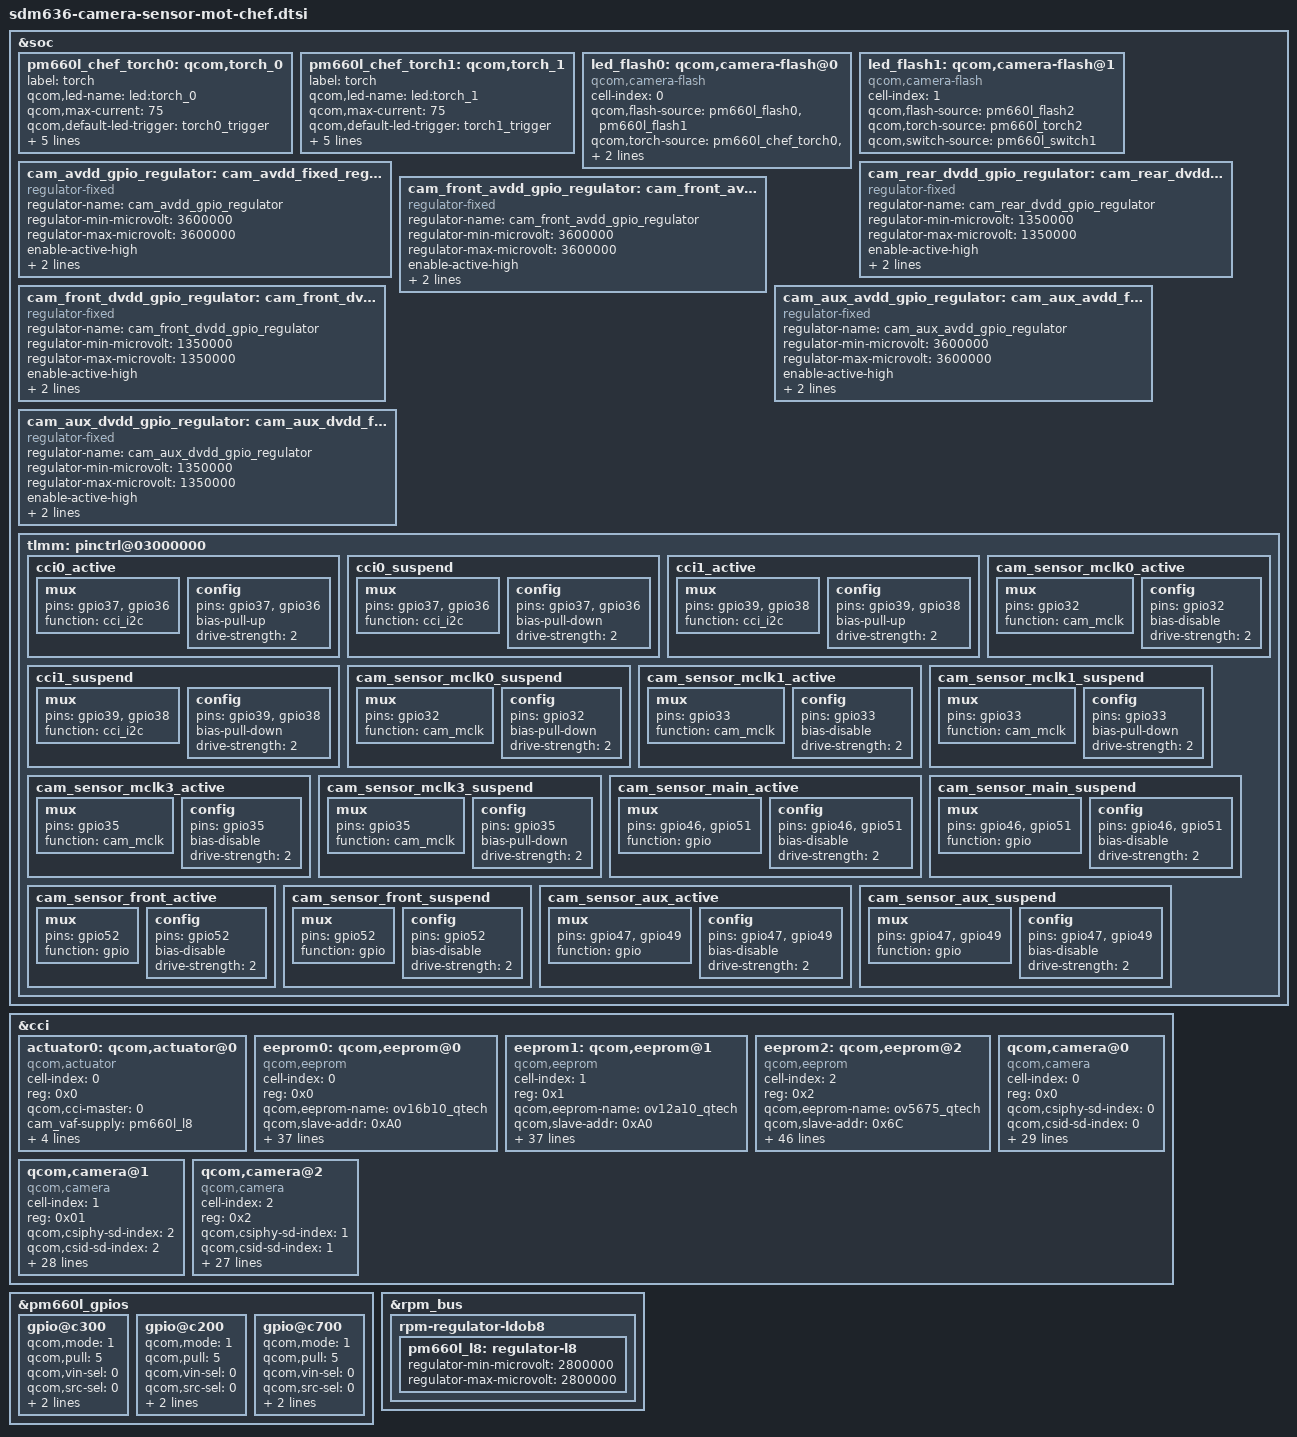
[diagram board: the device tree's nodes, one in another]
/*
 * Copyright (c) 2016-2017, The Linux Foundation. All rights reserved.
 *
 * This program is free software; you can redistribute it and/or modify
 * it under the terms of the GNU General Public License version 2 and
 * only version 2 as published by the Free Software Foundation.
 *
 * This program is distributed in the hope that it will be useful,
 * but WITHOUT ANY WARRANTY; without even the implied warranty of
 * MERCHANTABILITY or FITNESS FOR A PARTICULAR PURPOSE.  See the
 * GNU General Public License for more details.
 */

&soc {
	pm660l_chef_torch0: qcom,torch_0 {
				label = "torch";
				qcom,led-name = "led:torch_0";
				qcom,max-current = <75>;
				qcom,default-led-trigger = "torch0_trigger";
				qcom,id = <0>;
				qcom,current-ma = <75>;
				qcom,ires-ua = <12500>;
				qcom,hdrm-voltage-mv = <325>;
				qcom,hdrm-vol-hi-lo-win-mv = <100>;
			};

	pm660l_chef_torch1: qcom,torch_1 {
				label = "torch";
				qcom,led-name = "led:torch_1";
				qcom,max-current = <75>;
				qcom,default-led-trigger = "torch1_trigger";
				qcom,id = <1>;
				qcom,current-ma = <75>;
				qcom,ires-ua = <12500>;
				qcom,hdrm-voltage-mv = <325>;
				qcom,hdrm-vol-hi-lo-win-mv = <100>;
			};

	led_flash0: qcom,camera-flash@0 {
		cell-index = <0>;
		compatible = "qcom,camera-flash";
		qcom,flash-source = <&pm660l_flash0 &pm660l_flash1>;
		qcom,torch-source = <&pm660l_chef_torch0 &pm660l_chef_torch1>;
		qcom,switch-source = <&pm660l_switch0>;
		status = "ok";
	};

	led_flash1: qcom,camera-flash@1 {
		cell-index = <1>;
		compatible = "qcom,camera-flash";
		qcom,flash-source = <&pm660l_flash2>;
		qcom,torch-source = <&pm660l_torch2>;
		qcom,switch-source = <&pm660l_switch1>;
		status = "ok";
	};

	cam_avdd_gpio_regulator: cam_avdd_fixed_regulator {
		compatible = "regulator-fixed";
		regulator-name = "cam_avdd_gpio_regulator";
		regulator-min-microvolt = <3600000>;
		regulator-max-microvolt = <3600000>;
		enable-active-high;
		gpio = <&tlmm 51 0>;
		vin-supply = <&pm660l_bob>;
	};

	cam_rear_dvdd_gpio_regulator: cam_rear_dvdd_fixed_regulator {
		compatible = "regulator-fixed";
		regulator-name = "cam_rear_dvdd_gpio_regulator";
		regulator-min-microvolt = <1350000>;
		regulator-max-microvolt = <1350000>;
		enable-active-high;
		gpio = <&pm660l_gpios 4 0>;
		vin-supply = <&pm660_s5>;
	};

	cam_front_avdd_gpio_regulator: cam_front_avdd_fixed_regulator {
		compatible = "regulator-fixed";
		regulator-name = "cam_front_avdd_gpio_regulator";
		regulator-min-microvolt = <3600000>;
		regulator-max-microvolt = <3600000>;
		enable-active-high;
		gpio = <&tlmm 49 0>;
		vin-supply = <&pm660l_bob>;
	};

	cam_front_dvdd_gpio_regulator: cam_front_dvdd_fixed_regulator {
		compatible = "regulator-fixed";
		regulator-name = "cam_front_dvdd_gpio_regulator";
		regulator-min-microvolt = <1350000>;
		regulator-max-microvolt = <1350000>;
		enable-active-high;
		gpio = <&pm660l_gpios 8 0>;
		vin-supply = <&pm660_s5>;
	};

	cam_aux_avdd_gpio_regulator: cam_aux_avdd_fixed_regulator {
		compatible = "regulator-fixed";
		regulator-name = "cam_aux_avdd_gpio_regulator";
		regulator-min-microvolt = <3600000>;
		regulator-max-microvolt = <3600000>;
		enable-active-high;
		gpio = <&tlmm 49 0>;
		vin-supply = <&pm660l_bob>;
	};

	cam_aux_dvdd_gpio_regulator: cam_aux_dvdd_fixed_regulator {
		compatible = "regulator-fixed";
		regulator-name = "cam_aux_dvdd_gpio_regulator";
		regulator-min-microvolt = <1350000>;
		regulator-max-microvolt = <1350000>;
		enable-active-high;
		gpio = <&pm660l_gpios 3 0>;
		vin-supply = <&pm660_s5>;
	};

};

&cci {
	actuator0: qcom,actuator@0 {
		cell-index = <0>;
		reg = <0x0>;
		compatible = "qcom,actuator";
		qcom,cci-master = <0>;
		cam_vaf-supply = <&pm660l_l8>;
		qcom,cam-vreg-name = "cam_vaf";
		qcom,cam-vreg-min-voltage = <2800000>;
		qcom,cam-vreg-max-voltage = <2800000>;
		qcom,cam-vreg-op-mode = <80000>;
	};

	eeprom0: qcom,eeprom@0 {
		cell-index = <0>;
		reg = <0x0>;
		compatible = "qcom,eeprom";
		qcom,eeprom-name = "ov16b10_qtech";
		qcom,slave-addr = <0xA0>;
		qcom,cci-master = <0>;
		qcom,num-blocks = <1>;

		qcom,page0 = <0 0x0 2 0x01 1 1>;
		qcom,poll0 = <0 0x0 2 0 1 1>;
		qcom,mem0 = <0x0F4E 0x0 2 0 1 0>;

		cam_vio-supply = <&pm660_l11>;
		cam_vana-supply = <&cam_avdd_gpio_regulator>;
		cam_vdig-supply = <&cam_rear_dvdd_gpio_regulator>;
		qcom,cam-vreg-name = "cam_vio", "cam_vana", "cam_vdig";
		qcom,cam-vreg-min-voltage = <1780000 0 0>;
		qcom,cam-vreg-max-voltage = <1950000 0 0>;
		qcom,cam-vreg-op-mode = <105000 0 0>;
		qcom,gpio-no-mux = <0>;
		pinctrl-names = "cam_default", "cam_suspend";
		pinctrl-0 = <&cam_sensor_mclk0_active
				&cam_sensor_main_active>;
		pinctrl-1 = <&cam_sensor_mclk0_suspend
				&cam_sensor_main_suspend>;
		gpios = <&tlmm 32 0>,
			<&tlmm 46 0>;
		qcom,gpio-reset = <1>;
		qcom,gpio-req-tbl-num = <0 1>;
		qcom,gpio-req-tbl-flags = <1 0>;
		qcom,gpio-req-tbl-label = "CAMIF_MCLK0", "CAM_RESET0";

		qcom,cam-power-seq-type =
			"sensor_gpio",
			"sensor_vreg",
			"sensor_vreg",
			"sensor_vreg",
			"sensor_gpio";
		qcom,cam-power-seq-val =
			"sensor_gpio_reset",
			"cam_vio",
			"cam_vana",
			"cam_vdig",
			"sensor_gpio_reset";
		qcom,cam-power-seq-cfg-val = <0 1 1 1 1>;
		qcom,cam-power-seq-delay = <5 1 1 5 10>;

		qcom,sensor-position = <0>;
		qcom,sensor-mode = <0>;
		status = "ok";
		clocks = <&clock_mmss MCLK0_CLK_SRC>,
				<&clock_mmss MMSS_CAMSS_MCLK0_CLK>;
		clock-names = "cam_src_clk", "cam_clk";
		qcom,clock-rates = <24000000 0>;
	};

	eeprom1: qcom,eeprom@1{
		cell-index = <1>;
		reg = <0x1>;
		qcom,eeprom-name = "ov12a10_qtech";
		compatible = "qcom,eeprom";
		qcom,slave-addr = <0xA0>;
		qcom,cci-master = <1>;
		qcom,num-blocks = <1>;

		qcom,page0 = <0 0x0 2 0x01 1 1>;
		qcom,poll0 = <0 0x0 2 0 1 1>;
		qcom,mem0 = <0x0709 0x0000 2 0 1 0>;

		cam_vio-supply = <&pm660_l11>;
		cam_vana-supply = <&cam_front_avdd_gpio_regulator>;
		cam_vdig-supply = <&cam_front_dvdd_gpio_regulator>;
		qcom,cam-vreg-name = "cam_vio", "cam_vana", "cam_vdig";
		qcom,cam-vreg-min-voltage = <1780000 0 0>;
		qcom,cam-vreg-max-voltage = <1950000 0 0>;
		qcom,cam-vreg-op-mode = <105000 0 0>;
		qcom,gpio-no-mux = <0>;
		pinctrl-names = "cam_default", "cam_suspend";
		pinctrl-0 = <&cam_sensor_mclk1_active
				 &cam_sensor_front_active>;
		pinctrl-1 = <&cam_sensor_mclk1_suspend
				 &cam_sensor_front_suspend>;
		gpios = <&tlmm 33 0>,
					<&tlmm 52 0>;
		qcom,gpio-reset = <1>;
		qcom,gpio-req-tbl-num = <0 1>;
		qcom,gpio-req-tbl-flags = <1 0>;
		qcom,gpio-req-tbl-label = "CAMIF_MCLK2", "CAM_RESET2";

		qcom,cam-power-seq-type =
			"sensor_gpio",
			"sensor_vreg",
			"sensor_vreg",
			"sensor_vreg",
			"sensor_gpio",
			"sensor_clk";
		qcom,cam-power-seq-val =
			"sensor_gpio_reset",
			"cam_vio",
			"cam_vana",
			"cam_vdig",
			"sensor_gpio_reset",
			"sensor_cam_mclk";
		qcom,cam-power-seq-cfg-val = <0 1 1 1 1 24000000>;
		qcom,cam-power-seq-delay = <5 1 1 5 10 10>;

		qcom,sensor-position = <1>;
		qcom,sensor-mode = <0>;
		status = "ok";
		clocks = <&clock_mmss MCLK1_CLK_SRC>,
			<&clock_mmss MMSS_CAMSS_MCLK1_CLK>;
		clock-names = "cam_src_clk", "cam_clk";
		qcom,clock-rates = <24000000 0>;
	};

	eeprom2: qcom,eeprom@2 {
		cell-index = <2>;
		reg = <0x2>;
		qcom,eeprom-name = "ov5675_qtech";
		compatible = "qcom,eeprom";
		qcom,slave-addr = <0x6C>;
		qcom,cci-master = <1>;
		qcom,num-blocks = <4>;

		qcom,page0 = <1 0x3d88 2 0x7010 2 1>;
		qcom,poll0 = <1 0x3d88 2 0x7010 2 1>;
		qcom,mem0 = <0 0x7010 2 0 1 1>;
		qcom,page1 = <1 0x3d8a 2 0x7045 2 1>;
		qcom,poll1 = <1 0x3d8a 2 0x7045 2 1>;
		qcom,mem1 = <0 0x7010 2 0 1 1>;
		qcom,page2 = <1 0x3d81 2 0x01 1 1>;
		qcom,poll2 = <1 0x3d81 2 0x01 1 1>;
		qcom,mem2 = <0 0x7010 2 0 1 1>;
		qcom,page3 = <1 0x0100 2 0x1 1 1>;
		qcom,poll3 = <0 0x0100 2 0x1 1 1>;
		qcom,mem3 = <54 0x7010 2 0 1 1>;

		cam_vio-supply = <&pm660_l11>;
		cam_vana-supply = <&cam_aux_avdd_gpio_regulator>;
		cam_vdig-supply = <&cam_aux_dvdd_gpio_regulator>;
		qcom,cam-vreg-name = "cam_vio", "cam_vana", "cam_vdig";
		qcom,cam-vreg-min-voltage = <1780000 0 0>;
		qcom,cam-vreg-max-voltage = <1950000 0 0>;
		qcom,cam-vreg-op-mode = <105000 0 0>;
		qcom,gpio-no-mux = <0>;
		pinctrl-names = "cam_default", "cam_suspend";
		pinctrl-0 = <&cam_sensor_mclk3_active
				&cam_sensor_aux_active>;
		pinctrl-1 = <&cam_sensor_mclk3_suspend
				&cam_sensor_aux_suspend>;
		gpios = <&tlmm 35 0>,
			<&tlmm 47 0>;
		qcom,gpio-reset = <1>;
		qcom,gpio-req-tbl-num = <0 1>;
		qcom,gpio-req-tbl-flags = <1 0>;
		qcom,gpio-req-tbl-label = "CAMIF_MCLK2","CAM_RESET2";

		qcom,cam-power-seq-type =
			"sensor_gpio",
			"sensor_vreg",
			"sensor_vreg",
			"sensor_vreg",
			"sensor_gpio",
			"sensor_clk";
		qcom,cam-power-seq-val =
			"sensor_gpio_reset",
			"cam_vio",
			"cam_vana",
			"cam_vdig",
			"sensor_gpio_reset",
			"sensor_cam_mclk";
		qcom,cam-power-seq-cfg-val = <0 1 1 1 1 24000000>;
		qcom,cam-power-seq-delay = <5 1 1 5 10 10>;

		qcom,sensor-position = <1>;
		qcom,sensor-mode = <0>;
		status = "ok";
		clocks = <&clock_mmss MCLK3_CLK_SRC>,
		    <&clock_mmss MMSS_CAMSS_MCLK3_CLK>;
		clock-names = "cam_src_clk", "cam_clk";
		qcom,clock-rates = <24000000 0>;
	};

	qcom,camera@0 {
		cell-index = <0>;
		compatible = "qcom,camera";
		reg = <0x0>;
		qcom,csiphy-sd-index = <0>;
		qcom,csid-sd-index = <0>;
		qcom,mount-angle = <90>;
		qcom,led-flash-src = <&led_flash0>;
		qcom,actuator-src = <&actuator0>;
		//qcom,ois-src = <&ois0>;
		qcom,eeprom-src = <&eeprom0>;
		cam_vio-supply = <&pm660_l11>;
		cam_vana-supply = <&cam_avdd_gpio_regulator>;
		cam_vdig-supply = <&cam_rear_dvdd_gpio_regulator>;
		qcom,cam-vreg-name = "cam_vio", "cam_vana", "cam_vdig";
		qcom,cam-vreg-min-voltage = <1780000 0 0>;
		qcom,cam-vreg-max-voltage = <1950000 0 0>;
		qcom,cam-vreg-op-mode = <105000 0 0>;
		qcom,gpio-no-mux = <0>;
		pinctrl-names = "cam_default", "cam_suspend";
		pinctrl-0 = <&cam_sensor_mclk0_active
				 &cam_sensor_main_active>;
		pinctrl-1 = <&cam_sensor_mclk0_suspend
				 &cam_sensor_main_suspend>;
		gpios = <&tlmm 32 0>,
			<&tlmm 46 0>;
		qcom,gpio-reset = <1>;
		qcom,gpio-req-tbl-num = <0 1>;
		qcom,gpio-req-tbl-flags = <1 0>;
		qcom,gpio-req-tbl-label = "CAMIF_MCLK0",
					"CAM_RESET0";
		qcom,sensor-position = <0>;
		qcom,sensor-mode = <0>;
		qcom,cci-master = <0>;
		status = "ok";
		clocks = <&clock_mmss MCLK0_CLK_SRC>,
				<&clock_mmss MMSS_CAMSS_MCLK0_CLK>;
		clock-names = "cam_src_clk", "cam_clk";
		qcom,clock-rates = <24000000 0>;
	};
	 qcom,camera@1{
		cell-index = <1>;
		compatible = "qcom,camera";
		reg = <0x01>;
		qcom,csiphy-sd-index = <2>;
		qcom,csid-sd-index = <2>;
		qcom,mount-angle = <270>;
		qcom,led-flash-src = <&led_flash1>;
		qcom,eeprom-src = <&eeprom1>;
		cam_vio-supply = <&pm660_l11>;
		cam_vana-supply = <&cam_front_avdd_gpio_regulator>;
		cam_vdig-supply = <&cam_front_dvdd_gpio_regulator>;
		qcom,cam-vreg-name = "cam_vio", "cam_vana", "cam_vdig";
		qcom,cam-vreg-min-voltage = <1780000 0 0>;
		qcom,cam-vreg-max-voltage = <1950000 0 0>;
		qcom,cam-vreg-op-mode = <105000 0 0>;
		qcom,gpio-no-mux = <0>;
		pinctrl-names = "cam_default", "cam_suspend";
		pinctrl-0 = <&cam_sensor_mclk1_active
				&cam_sensor_front_active>;
		pinctrl-1 = <&cam_sensor_mclk1_suspend
				&cam_sensor_front_suspend>;
		gpios = <&tlmm 33 0>,
			<&tlmm 52 0>;
		qcom,gpio-reset = <1>;
		qcom,gpio-req-tbl-num = <0 1>;
		qcom,gpio-req-tbl-flags = <1 0>;
		qcom,gpio-req-tbl-label = "CAMIF_MCLK2",
						"CAM_RESET2";
		qcom,sensor-position = <1>;
		qcom,sensor-mode = <0>;
		qcom,cci-master = <1>;
		status = "ok";
		clocks = <&clock_mmss MCLK1_CLK_SRC>,
			<&clock_mmss MMSS_CAMSS_MCLK1_CLK>;
		clock-names = "cam_src_clk", "cam_clk";
		qcom,clock-rates = <24000000 0>;
	};

	//sub camera
	qcom,camera@2 {
		cell-index = <2>;
		compatible = "qcom,camera";
		reg = <0x2>;
		qcom,csiphy-sd-index = <1>;
		qcom,csid-sd-index = <1>;
		qcom,mount-angle = <90>;
		qcom,eeprom-src = <&eeprom2>;
		cam_vio-supply = <&pm660_l11>;
		cam_vana-supply = <&cam_aux_avdd_gpio_regulator>;
		cam_vdig-supply = <&cam_aux_dvdd_gpio_regulator>;
		qcom,cam-vreg-name = "cam_vio", "cam_vana", "cam_vdig";
		qcom,cam-vreg-min-voltage = <1780000 0 0>;
		qcom,cam-vreg-max-voltage = <1950000 0 0>;
		qcom,cam-vreg-op-mode = <105000 0 0>;
		qcom,gpio-no-mux = <0>;
		pinctrl-names = "cam_default", "cam_suspend";
		pinctrl-0 = <&cam_sensor_mclk3_active
				 &cam_sensor_aux_active>;
		pinctrl-1 = <&cam_sensor_mclk3_suspend
				 &cam_sensor_aux_suspend>;
		gpios = <&tlmm 35 0>,
			<&tlmm 47 0>;
		qcom,gpio-reset = <1>;
		qcom,gpio-req-tbl-num = <0 1>;
		qcom,gpio-req-tbl-flags = <1 0>;
		qcom,gpio-req-tbl-label = "CAMIF_MCLK2",
					"CAM_RESET2";
		qcom,sensor-position = <1>;
		qcom,sensor-mode = <0>;
		qcom,cci-master = <1>;
		status = "ok";
		clocks = <&clock_mmss MCLK3_CLK_SRC>,
			<&clock_mmss MMSS_CAMSS_MCLK3_CLK>;
		clock-names = "cam_src_clk", "cam_clk";
		qcom,clock-rates = <24000000 0>;
	};
};

&pm660l_gpios {
	gpio@c300 { /* GPIO4 -CAMERA SENSOR 0 VDIG*/
		qcom,mode = <1>;                /* Output */
		qcom,pull = <5>;                /* No Pull */
		qcom,vin-sel = <0>;             /* VIN1 GPIO_LV */
		qcom,src-sel = <0>;             /* GPIO */
		qcom,invert = <0>;              /* Invert */
		qcom,master-en = <1>;           /* Enable GPIO */
		status = "ok";
	};

	gpio@c200 { /* GPIO3 -CAMERA SENSOR 2 VDIG*/
		qcom,mode = <1>;                /* Output */
		qcom,pull = <5>;                /* No Pull */
		qcom,vin-sel = <0>;             /* VIN1 GPIO_LV */
		qcom,src-sel = <0>;             /* GPIO */
		qcom,invert = <0>;              /* Invert */
		qcom,master-en = <1>;           /* Enable GPIO */
		status = "ok";
	};

	gpio@c700 { /* GPIO8 -CAMERA SENSOR 2 VDIG*/
		qcom,mode = <1>;                /* Output */
		qcom,pull = <5>;                /* No Pull */
		qcom,vin-sel = <0>;             /* VIN1 GPIO_LV */
		qcom,src-sel = <0>;             /* GPIO */
		qcom,invert = <0>;              /* Invert */
		qcom,master-en = <1>;           /* Enable GPIO */
		status = "ok";
	};
};

&soc {
	tlmm: pinctrl@03000000 {
		cci0_active: cci0_active {
			mux {
				/* CLK, DATA */
				pins = "gpio37","gpio36"; // Only 2
				function = "cci_i2c";
			};

			config {
				pins = "gpio37","gpio36";
				bias-pull-up; /* PULL UP*/
				drive-strength = <2>; /* 2 MA */
			};
		};

		cci0_suspend: cci0_suspend {
			mux {
				/* CLK, DATA */
				pins = "gpio37","gpio36";
				function = "cci_i2c";
			};

			config {
				pins = "gpio37","gpio36";
				bias-pull-down; /* PULL DOWN */
				drive-strength = <2>; /* 2 MA */
			};
		};

		cci1_active: cci1_active {
			mux {
				/* CLK, DATA */
				pins = "gpio39","gpio38";
				function = "cci_i2c";
			};

			config {
				pins = "gpio39","gpio38";
				bias-pull-up; /* PULL UP*/
				drive-strength = <2>; /* 2 MA */
			};
		};

		cci1_suspend: cci1_suspend {
			mux {
				/* CLK, DATA */
				pins = "gpio39","gpio38";
				function = "cci_i2c";
			};


			config {
				pins = "gpio39","gpio38";
				bias-pull-down; /* PULL DOWN */
				drive-strength = <2>; /* 2 MA */
			};
		};

		cam_sensor_mclk0_active: cam_sensor_mclk0_active {
			/* MCLK0 */
			mux {
				/* CLK */
				pins = "gpio32";
				function = "cam_mclk";
			};

			config {
				pins = "gpio32";
				bias-disable; /* No PULL */
				drive-strength = <2>; /* 2 MA */
			};
		};

		cam_sensor_mclk0_suspend: cam_sensor_mclk0_suspend {
			/* MCLK0 */
			mux {
				/* CLK */
				pins = "gpio32";
				function = "cam_mclk";
			};

			config {
				pins = "gpio32";
				bias-pull-down; /* PULL DOWN */
				drive-strength = <2>; /* 2 MA */
			};
		};

		cam_sensor_mclk1_active: cam_sensor_mclk1_active {
			/* MCLK1 */
			mux {
				/* CLK */
				pins = "gpio33";
				function = "cam_mclk";
			};

			config {
				pins = "gpio33";
				bias-disable; /* No PULL */
				drive-strength = <2>; /* 2 MA */
			};
		};

		cam_sensor_mclk1_suspend: cam_sensor_mclk1_suspend {
			/* MCLK1 */
			mux {
				/* CLK */
				pins = "gpio33";
				function = "cam_mclk";
			};

			config {
				pins = "gpio33";
				bias-pull-down; /* PULL DOWN */
				drive-strength = <2>; /* 2 MA */
			};
		};

		cam_sensor_mclk3_active: cam_sensor_mclk3_active {
			/* MCLK3 */
			mux {
				/* CLK */
				pins = "gpio35";
				function = "cam_mclk";
			};

			config {
				pins = "gpio35";
				bias-disable; /* No PULL */
				drive-strength = <2>; /* 2 MA */
			};
		};

		cam_sensor_mclk3_suspend: cam_sensor_mclk3_suspend {
			/* MCLK3 */
			mux {
				/* CLK */
				pins = "gpio35";
				function = "cam_mclk";
			};

			config {
				pins = "gpio35";
				bias-pull-down; /* PULL DOWN */
				drive-strength = <2>; /* 2 MA */
			};
		};

		cam_sensor_main_active: cam_sensor_main_active {
			/* RESET, AVDD */
			mux {
				pins = "gpio46","gpio51";
				function = "gpio";
			};

			config {
				pins = "gpio46","gpio51";
				bias-disable; /* No PULL */
				drive-strength = <2>; /* 2 MA */
			};
		};

		cam_sensor_main_suspend: cam_sensor_main_suspend {
			/* RESET, AVDD */
			mux {
				pins = "gpio46","gpio51";
				function = "gpio";
			};

			config {
				pins = "gpio46","gpio51";
				bias-disable; /* No PULL */
				drive-strength = <2>; /* 2 MA */
			};
		};

		cam_sensor_front_active: cam_sensor_front_active {
			/* RESET  */
			mux {
				pins = "gpio52";
				function = "gpio";
			};

			config {
				pins = "gpio52";
				bias-disable; /* No PULL */
				drive-strength = <2>; /* 2 MA */
			};
		};

		cam_sensor_front_suspend: cam_sensor_front_suspend {
			/* RESET */
			mux {
				pins = "gpio52";
				function = "gpio";
			};

			config {
				pins = "gpio52";
				bias-disable; /* No PULL */
				drive-strength = <2>; /* 2 MA */
			};
		};

		cam_sensor_aux_active: cam_sensor_aux_active {
			/* RESET  VANA*/
			mux {
				pins = "gpio47", "gpio49";
				function = "gpio";
			};

			config {
				pins = "gpio47", "gpio49";
				bias-disable; /* No PULL */
				drive-strength = <2>; /* 2 MA */
			};
		};

		cam_sensor_aux_suspend: cam_sensor_aux_suspend {
			/* RESET VANA*/
			mux {
				pins = "gpio47", "gpio49";
				function = "gpio";
			};

			config {
				pins = "gpio47", "gpio49";
				bias-disable; /* No PULL */
				drive-strength = <2>; /* 2 MA */
			};
		};
	};
};

&rpm_bus {
	rpm-regulator-ldob8 {
		status = "okay";
		pm660l_l8: regulator-l8 {
			regulator-min-microvolt = <2800000>;
			regulator-max-microvolt = <2800000>;
			status = "okay";
		};
	};
};
